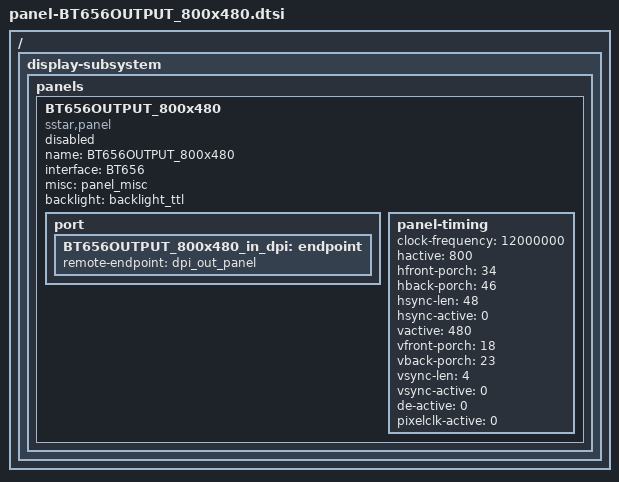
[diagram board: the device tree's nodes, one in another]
/*
* panel-BT656OUTPUT_800x480.dtsi- Sigmastar
*
* Copyright (c) [2019~2020] SigmaStar Technology.
*
*
* This software is licensed under the terms of the GNU General Public
* License version 2, as published by the Free Software Foundation, and
* may be copied, distributed, and modified under those terms.
*
* This program is distributed in the hope that it will be useful,
* but WITHOUT ANY WARRANTY; without even the implied warranty of
* MERCHANTABILITY or FITNESS FOR A PARTICULAR PURPOSE.  See the
* GNU General Public License version 2 for more details.
*
*/

/ {
    display-subsystem {
        panels {
            BT656OUTPUT_800x480 {
                compatible = "sstar,panel";
                name = "BT656OUTPUT_800x480";
                interface = "BT656"; /* TTL/MIPI/LVDS/BT1120/BT656/BT601 */
                misc = <&panel_misc>;
                backlight = <&backlight_ttl>;
                status = "disable";

                port {
                    BT656OUTPUT_800x480_in_dpi: endpoint {
                        remote-endpoint = <&dpi_out_panel>;
                    };
                };

                panel-timing {
                    clock-frequency = <12000000>;
                    hactive = <800>;
                    hfront-porch = <34>;
                    hback-porch = <46>;
                    hsync-len = <48>;
                    hsync-active = <0>;
                    vactive = <480>;
                    vfront-porch = <18>;
                    vback-porch = <23>;
                    vsync-len = <4>;
                    vsync-active = <0>;
                    de-active = <0>;
                    pixelclk-active = <0>;
                };
            };
        };
    };
};
